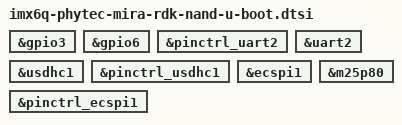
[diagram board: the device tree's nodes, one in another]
// SPDX-License-Identifier: GPL-2.0+
/*
 * Copyright (C) 2020
 * Niel Fourie, DENX Software Engineering, lusus@denx.de.
 */
#include "imx6qdl-u-boot.dtsi"

&gpio3 {
	u-boot,dm-spl;
};

&gpio6 {
	u-boot,dm-spl;
};

&pinctrl_uart2 {
	u-boot,dm-spl;
};

&uart2 {
	u-boot,dm-spl;
};

&usdhc1 {
	u-boot,dm-spl;
};

&pinctrl_usdhc1 {
	u-boot,dm-spl;
};

&ecspi1 {
	u-boot,dm-spl;
};

&pinctrl_ecspi1 {
	u-boot,dm-spl;
};

&m25p80 {
	u-boot,dm-spl;
};
